# STM32WBA52xx register map
File version: 1.0
Registers are 32-bit, read-write, reset 0x0 unless marked. A register's access mark holds for its fields unless they carry their own. Offsets are from the block's base; [hi:lo] are bit positions; {n}, {i} and the like mark numbered series; 'fields as' and 'values as' point back to an identical list.

## PKA
Base 0x420C2000
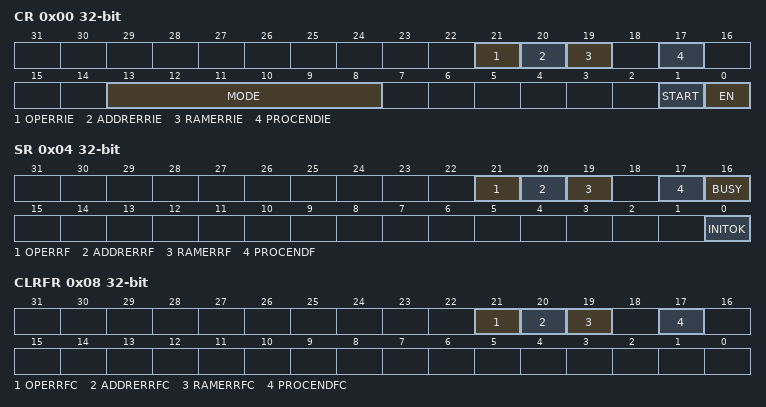
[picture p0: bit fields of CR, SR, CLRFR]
0x00 CR — PKA control register
  [21] OPERRIE — Operation Error interrupt enable
  [20] ADDRERRIE — Address error interrupt enable
  [19] RAMERRIE — RAM error interrupt enable
  [17] PROCENDIE — End of operation interrupt enable
  [13:8] MODE — MODE[5:0] PKA operation code
  [1] START — Start operation
  [0] EN — PKA enable
0x04 SR — PKA status register
  [21] OPERRF — PKA operation Error flag
  [20] ADDRERRF — Address error flag
  [19] RAMERRF — PKA RAM error flag
  [17] PROCENDF — PKA end of operation flag
  [16] BUSY — PKA operation is in progress
  [0] INITOK — PKA initialisation flag
0x08 CLRFR — PKA clear flag register
  [21] OPERRFC — Clear PKA operation Error flag
  [20] ADDRERRFC — Clear address error flag
  [19] RAMERRFC — Clear PKA RAM error flag
  [17] PROCENDFC — Clear PKA end of operation flag
{0x400+4i} RAM[{i}] (i=0..1333)

## SYSCFG — System configuration controller
Base 0x46000400
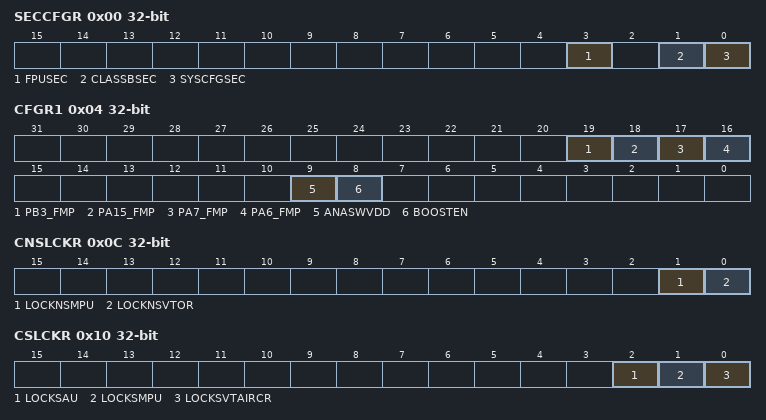
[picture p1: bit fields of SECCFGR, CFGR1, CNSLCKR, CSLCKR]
0x00 SECCFGR — SYSCFG secure configuration register
  [3] FPUSEC — FPU SYSCFG security enable
  [1] CLASSBSEC — ClassB SYSCFG security enable
  [0] SYSCFGSEC — SYSCFG clock control security enable
0x04 CFGR1 — SYSCFG configuration register 1
  [19] PB3_FMP — I2C PB3 Fast mode plus
  [18] PA15_FMP — I2C PA15 Fast mode plus
  [17] PA7_FMP — I2C PA7 Fast mode plus
  [16] PA6_FMP — I2C PA6 Fast mode plus
  [9] ANASWVDD — GPIO analog switch control voltage selection
  [8] BOOSTEN — I/O analog switch voltage booster enable
0x08 FPUIMR — SYSCFG FPU interrupt mask register
  [5:0] FPU_IE — All FPU interrupts enable
0x0C CNSLCKR — SYSCFG CPU non-secure lock register
  [1] LOCKNSMPU — Disable Non-Secure MPU registers writes by SW or debug agent
  [0] LOCKNSVTOR — Disable VTOR_NS register writes by SW or debug agent
0x10 CSLCKR — SYSCFG CPU secure lock register
  [2] LOCKSAU — Disable changes to SAU registers
  [1] LOCKSMPU — Disable changes to the secure MPU registers writes by SW or debug agent
  [0] LOCKSVTAIRCR — Disable changes to the secure vector table address, handling of system faults
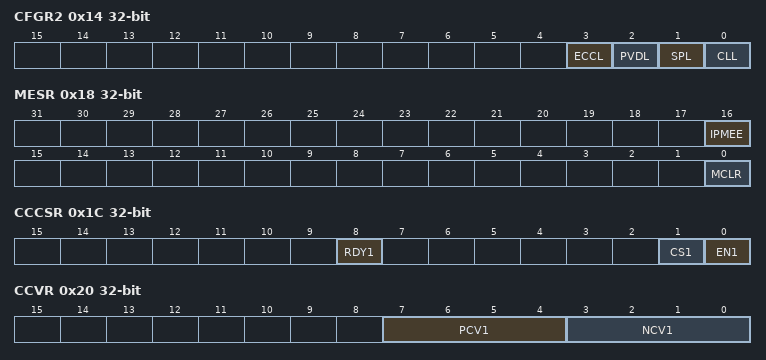
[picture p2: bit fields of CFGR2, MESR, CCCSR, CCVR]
0x14 CFGR2 — SYSCFG configuration register 2
  [3] ECCL — ECC Lock
  [2] PVDL — PVD Lock
  [1] SPL — SRAM Parity Lock
  [0] CLL — Core Lockup Lock
0x18 MESR — SYSCFG Memory Erase Status register
  [16] IPMEE — Status of End of Erase for ICache and PKA RAMs
  [0] MCLR — Status of Erase after Reset
0x1C CCCSR — SYSCFG Conpensation Cell Control&Status register
  [8] RDY1 — VDD compensation cell ready flag
  [1] CS1 — Code selection for VDD power rail
  [0] EN1 — Enable compensation cell for VDD power rail
0x20 CCVR — SYSCFG Conpensation Cell value register
  [7:4] PCV1 — PMOS compensation value for VDD Power Rail
  [3:0] NCV1 — NMOS compensation value for VDD Power Rail
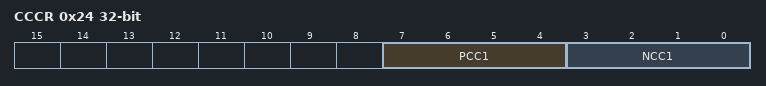
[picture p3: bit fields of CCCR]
0x24 CCCR — SYSCFG Conpensation Cell Code register
  [7:4] PCC1 — PMOS compensation code for VDD Power Rail
  [3:0] NCC1 — NMOS compensation code for VDD Power Rail
0x2C RSSCMDR — SYSCFG RSS command mode register
  [15:0] RSSCMD — RSS command

## TAMP — Tamper and backup registers
Base 0x46007C00
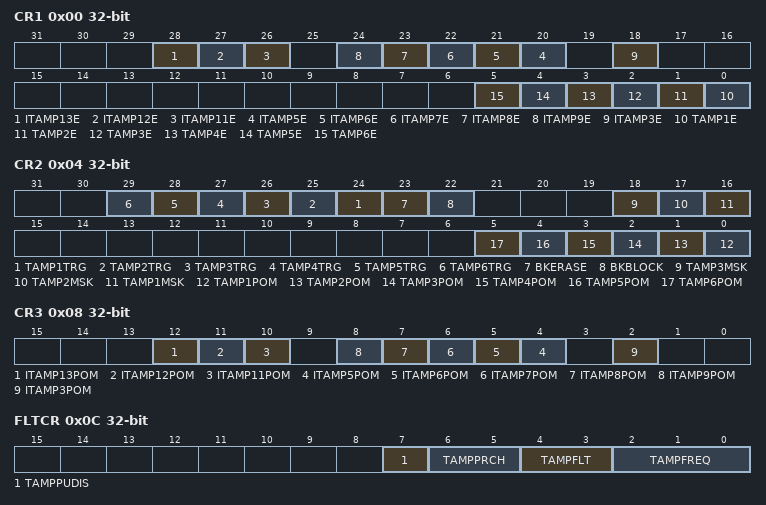
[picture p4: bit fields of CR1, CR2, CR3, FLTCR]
0x00 CR1 — TAMP configuration register 1
  [28] ITAMP13E, [27] ITAMP12E, [26] ITAMP11E, [n+15] ITAMP{n}E (n=5..9), [18] ITAMP3E, [n-1] TAMP{n}E (n=1..6)
0x04 CR2 — TAMP configuration register 2
  [n+23] TAMP{n}TRG (n=1..6), [23] BKERASE, [22] BKBLOCK, [18] TAMP3MSK, [17] TAMP2MSK, [16] TAMP1MSK, [n-1] TAMP{n}POM (n=1..6)
0x08 CR3 — TAMP configuration register 3
  [12] ITAMP13POM, [11] ITAMP12POM, [10] ITAMP11POM, [n-1] ITAMP{n}POM (n=5..9), [2] ITAMP3POM
0x0C FLTCR — TAMP filter control register
  [7] TAMPPUDIS
  [6:5] TAMPPRCH
    0=DURATION_1RTCCLK (Tamper pins are pre-charged before sampling during 1 RTCCLK cycle); 1=DURATION_2RTCCLK (Tamper pins are pre-charged before sampling during 2 RTCCLK cycles); 2=DURATION_4RTCCLK (Tamper pins are pre-charged before sampling during 4 RTCCLK cycles); 3=DURATION_8RTCCLK (Tamper pins are pre-charged before sampling during 8 RTCCLK cycles)
  [4:3] TAMPFLT
    0=DISABLE (Tamper filter is disabled); 1=FILTER_2SAMPLE (Tamper is activated after 2 consecutive samples at the active level); 2=FILTER_4SAMPLE (Tamper is activated after 4 consecutive samples at the active level); 3=FILTER_8SAMPLE (Tamper is activated after 8 consecutive samples at the active level)
  [2:0] TAMPFREQ
    0=SAMPLFREQDIV_32768 (Each of the tamper inputs are sampled with a frequency = RTCCLK / 32768); 1=SAMPLFREQDIV_16384 (Each of the tamper inputs are sampled with a frequency = RTCCLK / 16384); 2=SAMPLFREQDIV_8192 (Each of the tamper inputs are sampled with a frequency = RTCCLK / 8192); 3=SAMPLFREQDIV_4096 (Each of the tamper inputs are sampled with a frequency = RTCCLK / 4096); 4=SAMPLFREQDIV_2048 (Each of the tamper inputs are sampled with a frequency = RTCCLK / 2048); 5=SAMPLFREQDIV_1024 (Each of the tamper inputs are sampled with a frequency = RTCCLK / 1024); 6=SAMPLFREQDIV_512 (Each of the tamper inputs are sampled with a frequency = RTCCLK / 512); 7=SAMPLFREQDIV_256 (Each of the tamper inputs are sampled with a frequency = RTCCLK / 256)
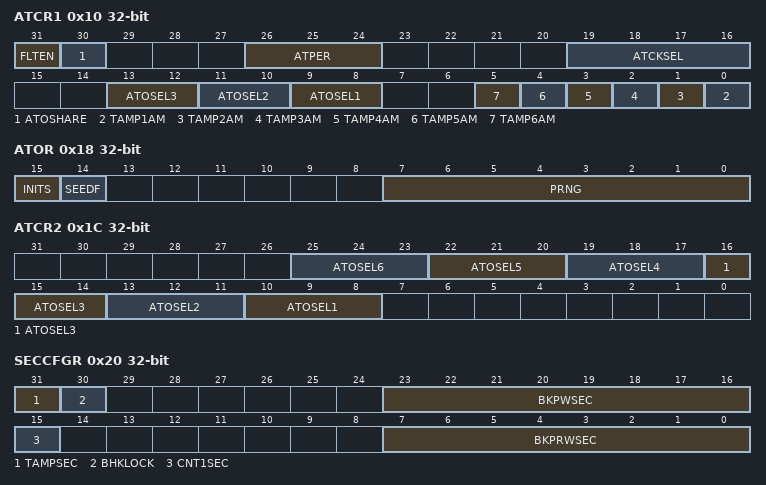
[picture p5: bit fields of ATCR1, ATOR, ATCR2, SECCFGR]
0x10 ATCR1 — TAMP filter control register 1
  [31] FLTEN, [30] ATOSHARE, [26:24] ATPER, [19:16] ATCKSEL, [13:12] ATOSEL3, [11:10] ATOSEL2, [9:8] ATOSEL1, [n-1] TAMP{n}AM (n=1..6)
0x14 ATSEEDR — TAMP active tamper seed register
  [31:0] SEED
0x18 ATOR — TAMP active tamper output register
  [15] INITS, [14] SEEDF, [7:0] PRNG
0x1C ATCR2 — TAMP filter control register 2
  [3n+7:3n+5] ATOSEL{n} (n=1..6)
0x20 SECCFGR — TAMP secure mode control register
  [31] TAMPSEC
    1=YES (TAMP full secure); 0=NO (TAMP is not secure)
  [30] BHKLOCK
  [23:16] BKPWSEC
  [15] CNT1SEC
  [7:0] BKPRWSEC
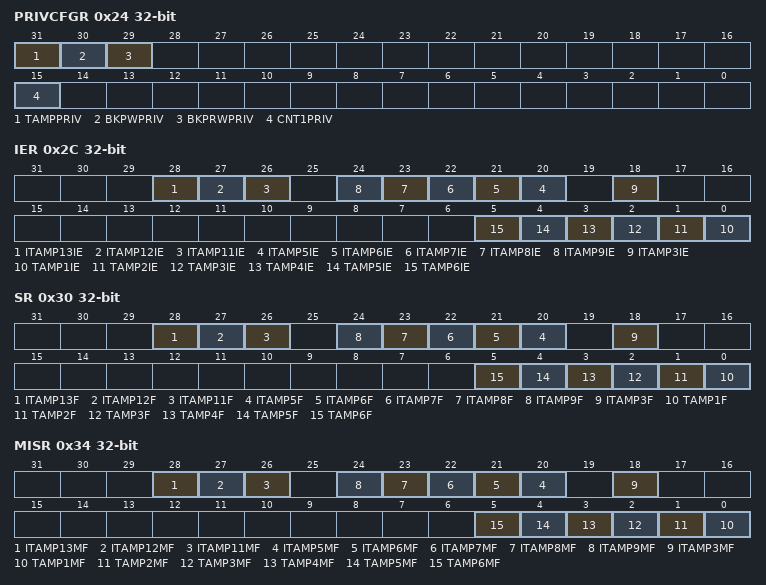
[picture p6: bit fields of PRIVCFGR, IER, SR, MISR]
0x24 PRIVCFGR — TAMP privilege mode control register
  [31] TAMPPRIV
    1=YES (TAMP full privilege); 0=NO (TAMP is not privilege)
  [30] BKPWPRIV
  [29] BKPRWPRIV
  [15] CNT1PRIV
0x2C IER — TAMP interrupt enable register
  [28] ITAMP13IE, [27] ITAMP12IE, [26] ITAMP11IE, [n+15] ITAMP{n}IE (n=5..9), [18] ITAMP3IE, [n-1] TAMP{n}IE (n=1..6)
0x30 SR — TAMP status register
  [28] ITAMP13F, [27] ITAMP12F, [26] ITAMP11F, [n+15] ITAMP{n}F (n=5..9), [18] ITAMP3F, [n-1] TAMP{n}F (n=1..6)
0x34 MISR — TAMP masked interrupt status register
  [28] ITAMP13MF, [27] ITAMP12MF, [26] ITAMP11MF, [n+15] ITAMP{n}MF (n=5..9), [18] ITAMP3MF, [n-1] TAMP{n}MF (n=1..6)
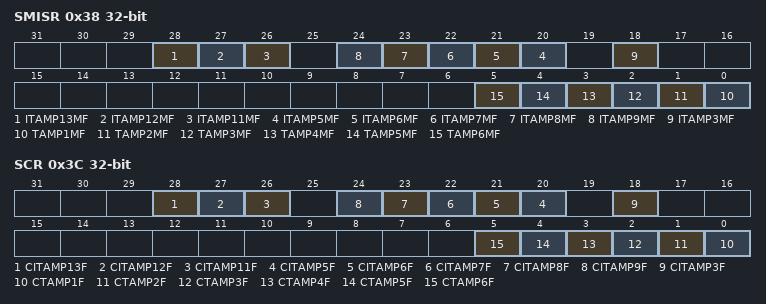
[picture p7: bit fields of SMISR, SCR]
0x38 SMISR — TAMP secure masked interrupt status register
  fields as MISR
0x3C SCR — TAMP status clear register
  [28] CITAMP13F, [27] CITAMP12F, [26] CITAMP11F, [n+15] CITAMP{n}F (n=5..9), [18] CITAMP3F, [n-1] CTAMP{n}F (n=1..6)
0x40 COUNT1R — TAMP monotonic counter 1 register
  [31:0] COUNT
0x54 RPCFGR — TAMP resources protection configuration register
  [5:1] RPCFG
{0x100+4i} BKP{i}R (i=0..31) — TAMP backup register {i}

## EXTI — Asynch Interrupt/Event Controller (EXTI)
Base 0x46022000
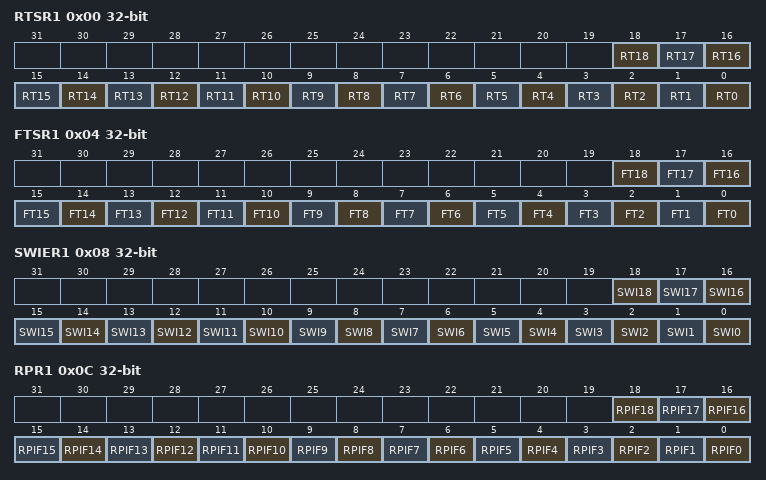
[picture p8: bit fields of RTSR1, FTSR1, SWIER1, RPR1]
0x00 RTSR1 — EXTI Rising Trigger Selection Register 1
  [n] RT{n} (n=0..18) — Rising trigger configuration for input line {n}
0x04 FTSR1 — EXTI Falling Trigger Selection Register 1
  [n] FT{n} (n=0..18) — Falling trigger configuration for input line {n}
0x08 SWIER1 — EXTI Software Interrupt event Register 1
  [n] SWI{n} (n=0..18) — Software Interrupt on line {n}
0x0C RPR1 — EXTI Rising Pending Register 1
  [n] RPIF{n} (n=0..18) — Rising Pending Interrupt Flag on line {n}
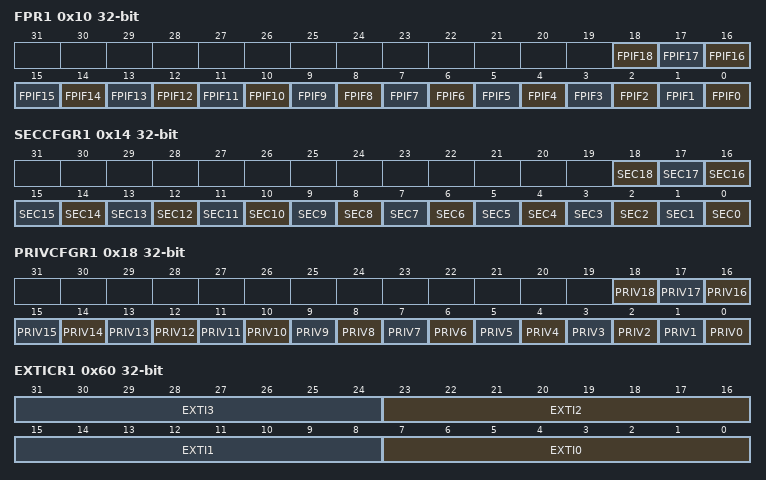
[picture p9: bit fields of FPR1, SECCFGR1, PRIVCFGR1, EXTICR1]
0x10 FPR1 — EXTI Falling Pending Register 1
  [n] FPIF{n} (n=0..18) — Falling Pending Interrupt Flag on line {n}
0x14 SECCFGR1 — EXTI Security Configuration Register 1
  [n] SEC{n} (n=0..18) — Security enable on line {n}
0x18 PRIVCFGR1 — EXTI Privilege Configuration Register 1
  [n] PRIV{n} (n=0..18) — Privilege enable on line {n}
0x60 EXTICR1 — EXIT External Interrupt Configuration Register, 0x60 -- 0x6C
  [8n+7:8n] EXTI{n} (n=0..3) — EXTI {n} configuration
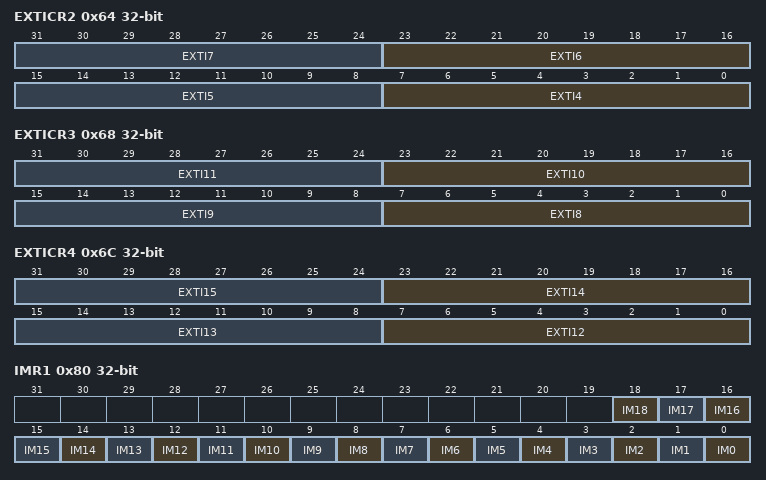
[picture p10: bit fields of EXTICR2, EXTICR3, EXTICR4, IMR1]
0x64 EXTICR2 — EXIT External Interrupt Configuration Register, 0x60 -- 0x6C
  [8n-25:8n-32] EXTI{n} (n=4..7) — EXTI {n} configuration
0x68 EXTICR3 — EXIT External Interrupt Configuration Register, 0x60 -- 0x6C
  [8n-57:8n-64] EXTI{n} (n=8..11) — EXTI {n} configuration
0x6C EXTICR4 — EXIT External Interrupt Configuration Register, 0x60 -- 0x6C
  [8n-89:8n-96] EXTI{n} (n=12..15) — EXTI {n} configuration
0x70 LOCKR — EXTI Lock Register
  [0] LOCK — Security and privilege configuration lock
0x80 IMR1 — EXTI Interrupt Mask Register 1
  [n] IM{n} (n=0..18) — Interrupt Mask on line {n}
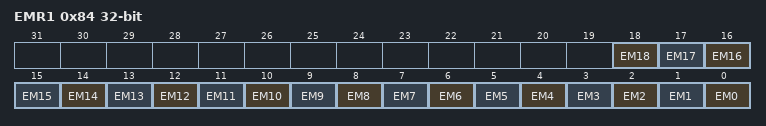
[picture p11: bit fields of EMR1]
0x84 EMR1 — EXTI Event Mask Register 1
  [n] EM{n} (n=0..18) — Event Mask on line {n}

## DBGMCU — Debug MCU
Base 0xE0044000
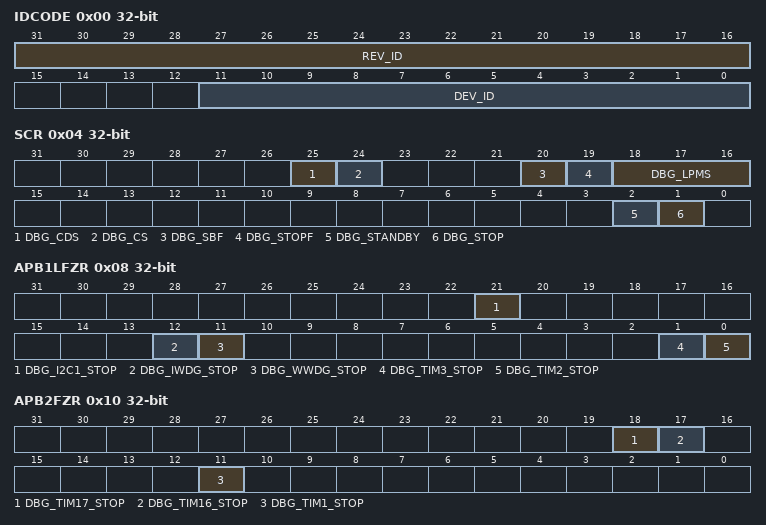
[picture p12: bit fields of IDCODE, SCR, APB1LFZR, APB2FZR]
0x00 IDCODE — MCU device ID code
  [31:16] REV_ID, [11:0] DEV_ID
0x04 SCR — Debug MCU status and configuration register
  [25] DBG_CDS, [24] DBG_CS, [20] DBG_SBF, [19] DBG_STOPF, [18:16] DBG_LPMS, [2] DBG_STANDBY, [1] DBG_STOP
0x08 APB1LFZR — Debug MCU APB1 freeze register 1
  [21] DBG_I2C1_STOP, [12] DBG_IWDG_STOP, [11] DBG_WWDG_STOP, [1] DBG_TIM3_STOP, [0] DBG_TIM2_STOP
0x0C APB1HFZR — Debug MCU APB1 freeze register 2
  [5] DBG_LPTIM2_STOP
0x10 APB2FZR — Debug MCU APB2 freeze register
  [18] DBG_TIM17_STOP, [17] DBG_TIM16_STOP, [11] DBG_TIM1_STOP
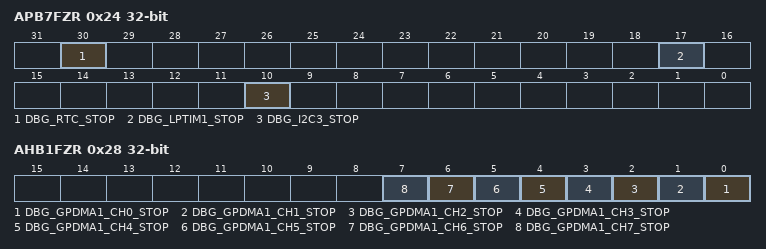
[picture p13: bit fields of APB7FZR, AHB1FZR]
0x24 APB7FZR — Debug MCU APB7 freeze register
  [30] DBG_RTC_STOP, [17] DBG_LPTIM1_STOP, [10] DBG_I2C3_STOP
0x28 AHB1FZR — Debug MCU AHB1 freeze register
  [n] DBG_GPDMA1_CH{n}_STOP (n=0..7)
